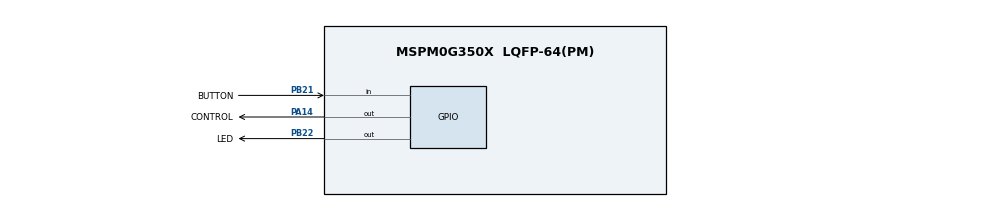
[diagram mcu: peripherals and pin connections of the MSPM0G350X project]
/**
 * @cliArgs --device "MSPM0G350X" --part "Default" --package "LQFP-64(PM)" --product "mspm0_sdk@2.10.00.04"
 * @versions {"tool":"1.26.2+4477"}
 */

const GPIO       = scripting.addModule("/ti/driverlib/GPIO", {}, false);
const MOS_CTRL   = GPIO.addInstance();
const USER_KEY   = GPIO.addInstance();
const STATUS_LED = GPIO.addInstance();
const SYSCTL     = scripting.addModule("/ti/driverlib/SYSCTL");

/* MOS module signal input: active high, safe low level after reset. */
MOS_CTRL.$name                                  = "MOS_CTRL";
MOS_CTRL.associatedPins[0].$name                = "CONTROL";
MOS_CTRL.associatedPins[0].initialValue         = "CLEARED";
MOS_CTRL.associatedPins[0].internalResistor     = "PULL_DOWN";
MOS_CTRL.associatedPins[0].pin.$assign          = "PA14";

/* On-board B21 key: pressed = low. */
USER_KEY.$name                                  = "USER_KEY";
USER_KEY.associatedPins[0].$name                = "BUTTON";
USER_KEY.associatedPins[0].direction            = "INPUT";
USER_KEY.associatedPins[0].internalResistor     = "PULL_UP";
USER_KEY.associatedPins[0].pin.$assign          = "PB21";

/* On-board status LED: high = on. */
STATUS_LED.$name                                = "STATUS_LED";
STATUS_LED.associatedPins[0].$name              = "LED";
STATUS_LED.associatedPins[0].initialValue       = "CLEARED";
STATUS_LED.associatedPins[0].internalResistor   = "PULL_DOWN";
STATUS_LED.associatedPins[0].pin.$assign        = "PB22";

const Board = scripting.addModule("/ti/driverlib/Board", {}, false);

SYSCTL.forceDefaultClkConfig = true;
Board.peripheral.$suggestSolution          = "DEBUGSS";
Board.peripheral.swclkPin.$suggestSolution = "PA20";
Board.peripheral.swdioPin.$suggestSolution = "PA19";
SYSCTL.peripheral.$suggestSolution         = "SYSCTL";
